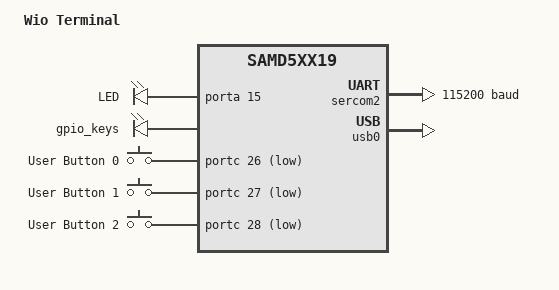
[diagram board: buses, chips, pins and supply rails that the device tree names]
/*
 * Copyright (c) 2021 Szymon Duchniewicz
 * Copyright (c) 2020 Google LLC.
 *
 * SPDX-License-Identifier: Apache-2.0
 */

/dts-v1/;
#include <atmel/samd5xx19.dtsi>

/ {
	model = "Wio Terminal";
	compatible = "seeed,wio-terminal";

	chosen {
		zephyr,console = &seeed_cdc_acm_uart;
		zephyr,shell-uart = &seeed_cdc_acm_uart;
		zephyr,sram = &sram0;
		zephyr,flash = &flash0;
		zephyr,code-partition = &code_partition;
	};

	/* These aliases are provided for compatibility with samples */
	aliases {
		led0 = &led0;
        sw0 = &user_button_0;
        sw1 = &user_button_1;
        sw2 = &user_button_2;
		//pwm-led0 = &pwm_led0;
		//pwm-0 = &tcc0;
	};

	leds {
		compatible = "gpio-leds";
		led0: led_0 {
			gpios = <&porta 15 0>;
			label = "LED";
		};
    gpio_keys {
        compatible = "gpio-keys";
        user_button_0: button_0 {
        label = "User Button 0";
        gpios = <&portc 26 1>;
        };
        user_button_1: button_1 {
        label = "User Button 1";
        gpios = <&portc 27 1>;
        };
        user_button_2: button_2 {
        label = "User Button 2";
        gpios = <&portc 28 1>;
        };
    };
	};

	//pwmleds {
	//	compatible = "pwm-leds";
	//	pwm_led0: pwm_led_0 {
	//		pwms = <&tcc0 2>;
	//	};
	//};
};

&cpu0 {
	clock-frequency = <120000000>;
};

//&sercom1 {
//    status = "okay";
//    compatible = "atmel,sam0-uart";
//    current-speed = <115200>;
//    rxpo = <1>;
//    txpo = <0>;
//
//    pinctrl-0 = <&pc22c_sercom1_pad0 &pc23c_sercom1_pad1>;
//};

&sercom2 {
	status = "okay";
	compatible = "atmel,sam0-uart";
	current-speed = <115200>;
	rxpo = <1>; // TODO maybe swap around?
	txpo = <0>;

    pinctrl-0 = <&pb27c_sercom2_pad1 &pb26c_sercom2_pad0>;
};


//
//&dmac {
//	status = "okay";
//};
//
&flash0 {
	partitions {
		compatible = "fixed-partitions";
		#address-cells = <1>;
		#size-cells = <1>;

		boot_partition: partition@0 {
			label = "uf2";
			reg = <0x00000000 DT_SIZE_K(16)>;
			read-only;
		};

		code_partition: partition@4000 {
			label = "code";
			reg = <0x4000 DT_SIZE_K(512-16)>; // -16
			read-only;
		};

		///*
		// * The final 16 KiB is reserved for the application.
		// * Storage partition will be used by FCB/LittleFS/NVS
		// * if enabled.
		// */
		//storage_partition: partition@7c000 {
		//	label = "storage";
		//	reg = <0x7c000 DT_SIZE_K(16)>;
		//};
	};
};

zephyr_udc0: &usb0 {
    compatible = "atmel,sam0-usb";
	status = "okay";

    seeed_cdc_acm_uart: seeed_cdc_acm_uart {
        compatible = "zephyr,cdc-acm-uart";
        label = "CDC_ACM_0";
    };
};
